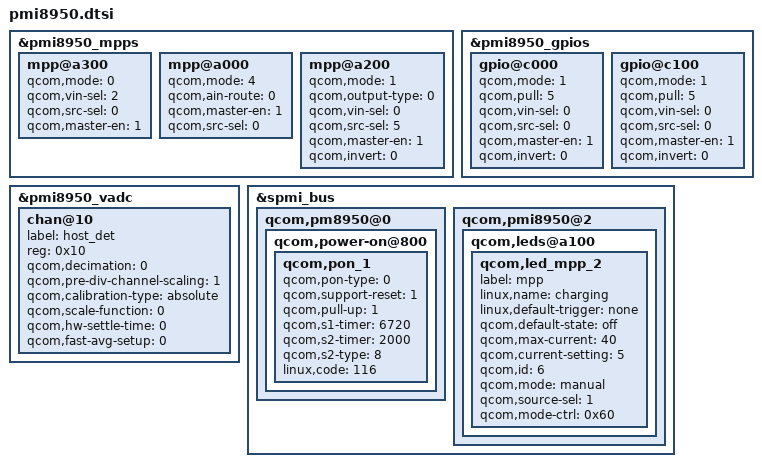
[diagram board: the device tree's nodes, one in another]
&pmi8950_mpps {
	mpp@a300 { /* MPP4 MOD_BPLUS_FAULT_N */
		qcom,mode = <0>;	/* Digital input */
		qcom,vin-sel = <2>;	/* 1.8 */
		qcom,src-sel = <0>;	/* GPIO */
		qcom,master-en = <1>;	/* Enable GPIO */
		status = "okay";
	};
};

&pmi8950_gpios {
	gpio@c000 { /* GPIO 1 - MOD_BPLUS_EN */
		qcom,mode = <1>;	/* Digital output */
		qcom,pull = <5>;	/* No Pull */
		qcom,vin-sel = <0>;	/* 1.8 */
		qcom,src-sel = <0>;	/* GPIO */
		qcom,master-en = <1>;	/* Enable GPIO */
		qcom,invert = <0>;	/* Output Low */
		status = "okay";
	};

	gpio@c100 {
		qcom,mode = <1>;	/* Digital output */
		qcom,pull = <5>;	/* No Pull */
		qcom,vin-sel = <0>;	/* 1.8 */
		qcom,src-sel = <0>;	/* GPIO */
		qcom,master-en = <1>;	/* Enable GPIO */
		qcom,invert = <0>;	/* Output Low */
		status = "okay";
	};
};

&pmi8950_mpps {
	mpp@a000 {
		/* Host detect */
		status = "ok";
		qcom,mode = <4>; /* AIN input */
		qcom,ain-route = <0>; /* AMUX 5 */
		qcom,master-en = <1>;
		qcom,src-sel = <0>; /* Function constant */
	};

	mpp@a200 {
		qcom,mode = <1>;		/* Digital output */
		qcom,output-type = <0>;		/* CMOS logic */
		qcom,vin-sel = <0>;
		qcom,src-sel = <5>;		/* DTEST2 */
		qcom,master-en = <1>;		/* Enable GPIO */
		qcom,invert = <0>;
		status = "okay";
	};
};

&pmi8950_vadc {
	chan@10 {
		label = "host_det";
		reg = <0x10>;
		qcom,decimation = <0>;
		qcom,pre-div-channel-scaling = <1>;
		qcom,calibration-type = "absolute";
		qcom,scale-function = <0>;
		qcom,hw-settle-time = <0>;
		qcom,fast-avg-setup = <0>;
	};
};

&spmi_bus {
	qcom,pm8950@0 {
		/delete-node/ qcom,leds@a300;
		qcom,power-on@800 {
			qcom,pon_1 {
				qcom,pon-type = <0>;
				qcom,support-reset = <1>;
				qcom,pull-up = <1>;
				qcom,s1-timer = <6720>;
				qcom,s2-timer = <2000>;
				qcom,s2-type = <8>;
				linux,code = <116>;
			};
		};
	};

	qcom,pmi8950@2 {
		qcom,leds@a100 {
			status = "okay";
			qcom,led_mpp_2 {
				label = "mpp";
				linux,name = "charging";
				linux,default-trigger = "none";
				qcom,default-state = "off";
				qcom,max-current = <40>;
				qcom,current-setting = <5>;
				qcom,id = <6>;
				qcom,mode = "manual";
				qcom,source-sel = <1>;
				qcom,mode-ctrl = <0x60>;
			};
		};
	};
};
